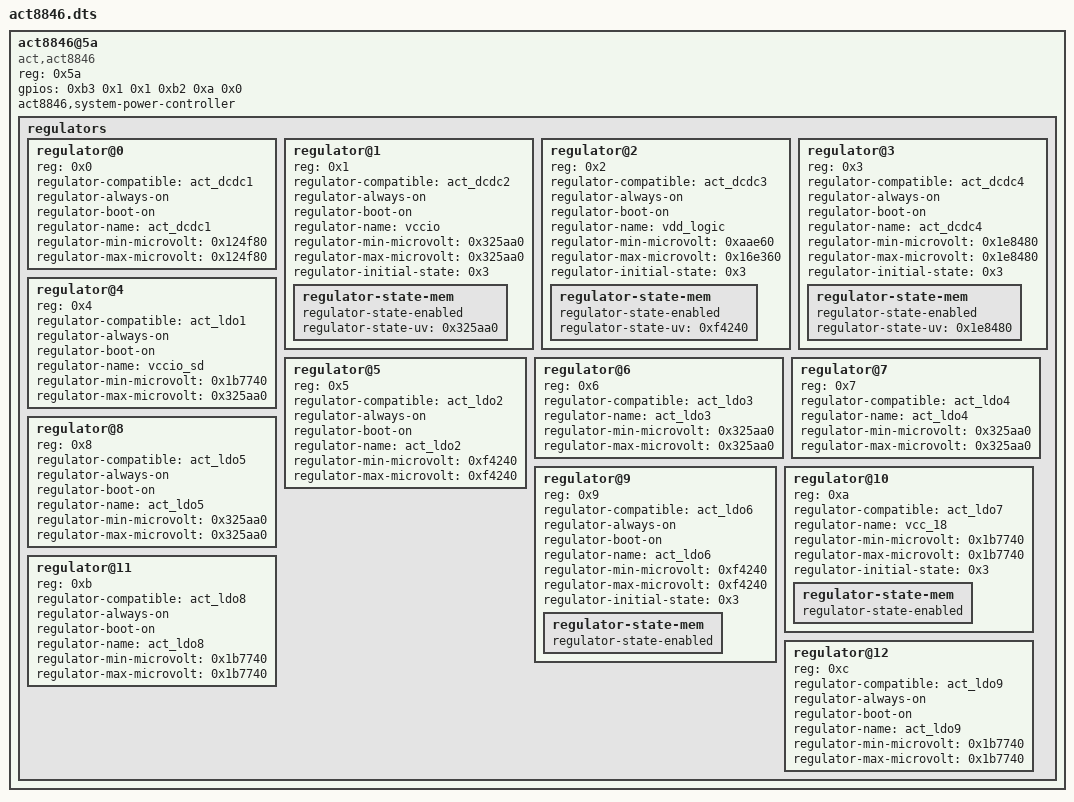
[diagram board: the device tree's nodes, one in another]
act8846@5a {
	reg = <0x5a>;
	status = "okay";
	compatible = "act,act8846";
	gpios = <0xb3 0x1 0x1 0xb2 0xa 0x0>;
	act8846,system-power-controller;

	regulators {
#address-cells = <0x1>;
#size-cells = <0x0>;

		regulator@0 {
			reg = <0x0>;
			regulator-compatible = "act_dcdc1";
			regulator-always-on;
			regulator-boot-on;
			regulator-name = "act_dcdc1";
			regulator-min-microvolt = <0x124f80>;
			regulator-max-microvolt = <0x124f80>;
		};

		regulator@1 {
			reg = <0x1>;
			regulator-compatible = "act_dcdc2";
			regulator-always-on;
			regulator-boot-on;
			regulator-name = "vccio";
			regulator-min-microvolt = <0x325aa0>;
			regulator-max-microvolt = <0x325aa0>;
			regulator-initial-state = <0x3>;

			regulator-state-mem {
				regulator-state-enabled;
				regulator-state-uv = <0x325aa0>;
			};
		};

		regulator@2 {
			reg = <0x2>;
			regulator-compatible = "act_dcdc3";
			regulator-always-on;
			regulator-boot-on;
			regulator-name = "vdd_logic";
			regulator-min-microvolt = <0xaae60>;
			regulator-max-microvolt = <0x16e360>;
			regulator-initial-state = <0x3>;

			regulator-state-mem {
				regulator-state-enabled;
				regulator-state-uv = <0xf4240>;
			};
		};

		regulator@3 {
			reg = <0x3>;
			regulator-compatible = "act_dcdc4";
			regulator-always-on;
			regulator-boot-on;
			regulator-name = "act_dcdc4";
			regulator-min-microvolt = <0x1e8480>;
			regulator-max-microvolt = <0x1e8480>;
			regulator-initial-state = <0x3>;

			regulator-state-mem {
				regulator-state-enabled;
				regulator-state-uv = <0x1e8480>;
			};
		};

		regulator@4 {
			reg = <0x4>;
			regulator-compatible = "act_ldo1";
			regulator-always-on;
			regulator-boot-on;
			regulator-name = "vccio_sd";
			regulator-min-microvolt = <0x1b7740>;
			regulator-max-microvolt = <0x325aa0>;
			linux,phandle = <0x7f>;
			phandle = <0x7f>;
		};

		regulator@5 {
			reg = <0x5>;
			regulator-compatible = "act_ldo2";
			regulator-always-on;
			regulator-boot-on;
			regulator-name = "act_ldo2";
			regulator-min-microvolt = <0xf4240>;
			regulator-max-microvolt = <0xf4240>;
			linux,phandle = <0x10d>;
			phandle = <0x10d>;
		};

		regulator@6 {
			reg = <0x6>;
			regulator-compatible = "act_ldo3";
			regulator-name = "act_ldo3";
			regulator-min-microvolt = <0x325aa0>;
			regulator-max-microvolt = <0x325aa0>;
			linux,phandle = <0x10e>;
			phandle = <0x10e>;
		};

		regulator@7 {
			reg = <0x7>;
			regulator-compatible = "act_ldo4";
			regulator-name = "act_ldo4";
			regulator-min-microvolt = <0x325aa0>;
			regulator-max-microvolt = <0x325aa0>;
			linux,phandle = <0xc2>;
			phandle = <0xc2>;
		};

		regulator@8 {
			reg = <0x8>;
			regulator-compatible = "act_ldo5";
			regulator-always-on;
			regulator-boot-on;
			regulator-name = "act_ldo5";
			regulator-min-microvolt = <0x325aa0>;
			regulator-max-microvolt = <0x325aa0>;
			linux,phandle = <0x10f>;
			phandle = <0x10f>;
		};

		regulator@9 {
			reg = <0x9>;
			regulator-compatible = "act_ldo6";
			regulator-always-on;
			regulator-boot-on;
			regulator-name = "act_ldo6";
			regulator-min-microvolt = <0xf4240>;
			regulator-max-microvolt = <0xf4240>;
			regulator-initial-state = <0x3>;
			linux,phandle = <0x110>;
			phandle = <0x110>;

			regulator-state-mem {
				regulator-state-enabled;
			};
		};

		regulator@10 {
			reg = <0xa>;
			regulator-compatible = "act_ldo7";
			regulator-name = "vcc_18";
			regulator-min-microvolt = <0x1b7740>;
			regulator-max-microvolt = <0x1b7740>;
			regulator-initial-state = <0x3>;
			linux,phandle = <0x111>;
			phandle = <0x111>;

			regulator-state-mem {
				regulator-state-enabled;
			};
		};

		regulator@11 {
			reg = <0xb>;
			regulator-compatible = "act_ldo8";
			regulator-always-on;
			regulator-boot-on;
			regulator-name = "act_ldo8";
			regulator-min-microvolt = <0x1b7740>;
			regulator-max-microvolt = <0x1b7740>;
			linux,phandle = <0x112>;
			phandle = <0x112>;
		};

		regulator@12 {
			reg = <0xc>;
			regulator-compatible = "act_ldo9";
			regulator-always-on;
			regulator-boot-on;
			regulator-name = "act_ldo9";
			regulator-min-microvolt = <0x1b7740>;
			regulator-max-microvolt = <0x1b7740>;
		};
	};
};
